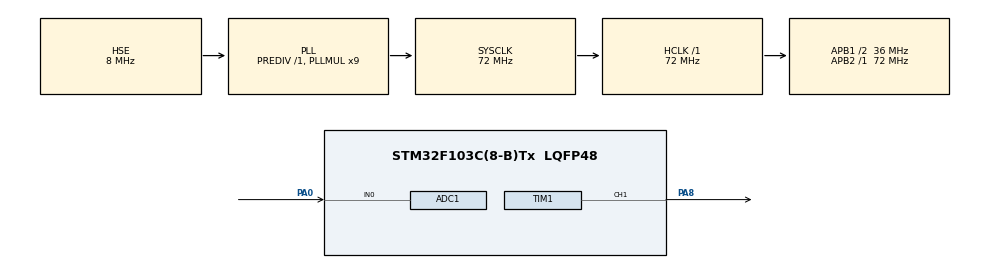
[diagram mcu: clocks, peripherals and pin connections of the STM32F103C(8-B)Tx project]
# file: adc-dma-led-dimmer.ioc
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ADC1.Channel-0\#ChannelRegularConversion=ADC_CHANNEL_0
ADC1.ContinuousConvMode=ENABLE
ADC1.NbrOfConversionFlag=1
ADC1.Rank-0\#ChannelRegularConversion=1
ADC1.SamplingTime-0\#ChannelRegularConversion=ADC_SAMPLETIME_1CYCLE_5
ADC1.master=1
Dma.ADC1.0.Direction=DMA_PERIPH_TO_MEMORY
Dma.ADC1.0.Instance=DMA1_Channel1
Dma.ADC1.0.MemDataAlignment=DMA_MDATAALIGN_WORD
Dma.ADC1.0.MemInc=DMA_MINC_ENABLE
Dma.ADC1.0.Mode=DMA_CIRCULAR
Dma.ADC1.0.PeriphDataAlignment=DMA_PDATAALIGN_WORD
Dma.ADC1.0.PeriphInc=DMA_PINC_DISABLE
Dma.ADC1.0.Priority=DMA_PRIORITY_LOW
Dma.Request0=ADC1
FREERTOS.BinarySemaphores01=adcSemaphore,Dynamic,NULL,Depleted
FREERTOS.Tasks01=defaultTask,24,128,StartDefaultTask,Default,NULL,Dynamic,NULL,NULL;ledCtrlTask,24,256,ledCtrlStrt,Default,NULL,Dynamic,NULL,NULL
FREERTOS.configTOTAL_HEAP_SIZE=10000
FREERTOS.configUSE_NEWLIB_REENTRANT=1
Mcu.Family=STM32F1
Mcu.Name=STM32F103C(8-B)Tx
Mcu.Package=LQFP48
NVIC.DMA1_Channel1_IRQn=true\:5\:0\:false\:false\:true\:true\:false\:true\:true
NVIC.PriorityGroup=NVIC_PRIORITYGROUP_4
NVIC.TIM2_IRQn=true\:15\:0\:false\:false\:true\:false\:false\:true\:true
NVIC.TimeBase=TIM2_IRQn
NVIC.TimeBaseIP=TIM2
PA0-WKUP.Signal=ADCx_IN0
PA8.Signal=S_TIM1_CH1
PD0-OSC_IN.Mode=HSE-External-Oscillator
PD0-OSC_IN.Signal=RCC_OSC_IN
PD1-OSC_OUT.Mode=HSE-External-Oscillator
PD1-OSC_OUT.Signal=RCC_OSC_OUT
ProjectManager.HeapSize=0x200
ProjectManager.StackSize=0x400
ProjectManager.TargetToolchain=STM32CubeIDE
RCC.ADCPresc=RCC_ADCPCLK2_DIV6
RCC.AHBFreq_Value=72000000
RCC.APB1CLKDivider=RCC_HCLK_DIV2
RCC.APB1Freq_Value=36000000
RCC.APB1TimFreq_Value=72000000
RCC.APB2Freq_Value=72000000
RCC.APB2TimFreq_Value=72000000
RCC.HCLKFreq_Value=72000000
RCC.PLLMUL=RCC_PLL_MUL9
RCC.PLLSourceVirtual=RCC_PLLSOURCE_HSE
RCC.SYSCLKFreq_VALUE=72000000
RCC.SYSCLKSource=RCC_SYSCLKSOURCE_PLLCLK
RCC.USBFreq_Value=72000000
SH.ADCx_IN0.0=ADC1_IN0,IN0
SH.S_TIM1_CH1.0=TIM1_CH1,PWM Generation1 CH1
TIM1.Channel-PWM\ Generation1\ CH1=TIM_CHANNEL_1
TIM1.Period=256 - 1
TIM1.Prescaler=72 - 1
VP_FREERTOS_VS_CMSIS_V2.Mode=CMSIS_V2
VP_SYS_VS_ND.Mode=No_Debug
VP_SYS_VS_tim2.Mode=TIM2
VP_TIM1_VS_ClockSourceINT.Mode=Internal
board=custom

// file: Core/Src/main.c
/* USER CODE BEGIN Header */
/**
  ******************************************************************************
  * @file           : main.c
  * @brief          : Main program body
  ******************************************************************************
  * @attention
  *
  * Copyright (c) 2024 STMicroelectronics.
  * All rights reserved.
  *
  * This software is licensed under terms that can be found in the LICENSE file
  * in the root directory of this software component.
  * If no LICENSE file comes with this software, it is provided AS-IS.
  *
  ******************************************************************************
  */
/* USER CODE END Header */
#include "main.h"
#include "cmsis_os.h"

/* USER CODE BEGIN PD */
#define BUFF_SIZE 16
/* USER CODE END PD */

ADC_HandleTypeDef hadc1;
DMA_HandleTypeDef hdma_adc1;

TIM_HandleTypeDef htim1;

/* Definitions for defaultTask */
osThreadId_t defaultTaskHandle;
const osThreadAttr_t defaultTask_attributes = {
  .name = "defaultTask",
  .stack_size = 128 * 4,
  .priority = (osPriority_t) osPriorityNormal,
};
/* Definitions for ledCtrlTask */
osThreadId_t ledCtrlTaskHandle;
const osThreadAttr_t ledCtrlTask_attributes = {
  .name = "ledCtrlTask",
  .stack_size = 256 * 4,
  .priority = (osPriority_t) osPriorityNormal,
};
/* Definitions for adcSemaphore */
osSemaphoreId_t adcSemaphoreHandle;
const osSemaphoreAttr_t adcSemaphore_attributes = {
  .name = "adcSemaphore"
};
/* USER CODE BEGIN PV */
volatile uint32_t adcBuff[BUFF_SIZE];
/* USER CODE END PV */

void SystemClock_Config(void);
static void MX_GPIO_Init(void);
static void MX_DMA_Init(void);
static void MX_ADC1_Init(void);
static void MX_TIM1_Init(void);
void StartDefaultTask(void *argument);
void ledCtrlStrt(void *argument);

int main(void)
{

  /* MCU Configuration--------------------------------------------------------*/

  /* Reset of all peripherals, Initializes the Flash interface and the Systick. */
  HAL_Init();

  /* Configure the system clock */
  SystemClock_Config();

  /* Initialize all configured peripherals */
  MX_GPIO_Init();
  MX_DMA_Init();
  MX_ADC1_Init();
  MX_TIM1_Init();
  /* USER CODE BEGIN 2 */
  //HAL_MspInit();
  HAL_TIM_PWM_Start(&htim1, TIM_CHANNEL_1);
  HAL_ADC_Start_DMA(&hadc1, adcBuff, BUFF_SIZE);
  //TIM1->CCR1 = 125;
  /* USER CODE END 2 */

  /* Init scheduler */
  osKernelInitialize();

  /* Create the semaphores(s) */
  /* creation of adcSemaphore */
  adcSemaphoreHandle = osSemaphoreNew(1, 0, &adcSemaphore_attributes);

  /* Create the thread(s) */
  /* creation of defaultTask */
  defaultTaskHandle = osThreadNew(StartDefaultTask, NULL, &defaultTask_attributes);

  /* creation of ledCtrlTask */
  ledCtrlTaskHandle = osThreadNew(ledCtrlStrt, NULL, &ledCtrlTask_attributes);

  /* Start scheduler */
  osKernelStart();

  /* We should never get here as control is now taken by the scheduler */

  /* Infinite loop */
  while (1)
  {

  }
}

void SystemClock_Config(void)
{
  RCC_OscInitTypeDef RCC_OscInitStruct = {0};
  RCC_ClkInitTypeDef RCC_ClkInitStruct = {0};
  RCC_PeriphCLKInitTypeDef PeriphClkInit = {0};

  /** Initializes the RCC Oscillators according to the specified parameters
  * in the RCC_OscInitTypeDef structure.
  */
  RCC_OscInitStruct.OscillatorType = RCC_OSCILLATORTYPE_HSE;
  RCC_OscInitStruct.HSEState = RCC_HSE_ON;
  RCC_OscInitStruct.HSEPredivValue = RCC_HSE_PREDIV_DIV1;
  RCC_OscInitStruct.HSIState = RCC_HSI_ON;
  RCC_OscInitStruct.PLL.PLLState = RCC_PLL_ON;
  RCC_OscInitStruct.PLL.PLLSource = RCC_PLLSOURCE_HSE;
  RCC_OscInitStruct.PLL.PLLMUL = RCC_PLL_MUL9;
  if (HAL_RCC_OscConfig(&RCC_OscInitStruct) != HAL_OK)
  {
    Error_Handler();
  }

  /** Initializes the CPU, AHB and APB buses clocks
  */
  RCC_ClkInitStruct.ClockType = RCC_CLOCKTYPE_HCLK|RCC_CLOCKTYPE_SYSCLK
                              |RCC_CLOCKTYPE_PCLK1|RCC_CLOCKTYPE_PCLK2;
  RCC_ClkInitStruct.SYSCLKSource = RCC_SYSCLKSOURCE_PLLCLK;
  RCC_ClkInitStruct.AHBCLKDivider = RCC_SYSCLK_DIV1;
  RCC_ClkInitStruct.APB1CLKDivider = RCC_HCLK_DIV2;
  RCC_ClkInitStruct.APB2CLKDivider = RCC_HCLK_DIV1;

  if (HAL_RCC_ClockConfig(&RCC_ClkInitStruct, FLASH_LATENCY_2) != HAL_OK)
  {
    Error_Handler();
  }
  PeriphClkInit.PeriphClockSelection = RCC_PERIPHCLK_ADC;
  PeriphClkInit.AdcClockSelection = RCC_ADCPCLK2_DIV6;
  if (HAL_RCCEx_PeriphCLKConfig(&PeriphClkInit) != HAL_OK)
  {
    Error_Handler();
  }
}

static void MX_ADC1_Init(void)
{

  ADC_ChannelConfTypeDef sConfig = {0};

  /** Common config
  */
  hadc1.Instance = ADC1;
  hadc1.Init.ScanConvMode = ADC_SCAN_DISABLE;
  hadc1.Init.ContinuousConvMode = ENABLE;
  hadc1.Init.DiscontinuousConvMode = DISABLE;
  hadc1.Init.ExternalTrigConv = ADC_SOFTWARE_START;
  hadc1.Init.DataAlign = ADC_DATAALIGN_RIGHT;
  hadc1.Init.NbrOfConversion = 1;
  if (HAL_ADC_Init(&hadc1) != HAL_OK)
  {
    Error_Handler();
  }

  /** Configure Regular Channel
  */
  sConfig.Channel = ADC_CHANNEL_0;
  sConfig.Rank = ADC_REGULAR_RANK_1;
  sConfig.SamplingTime = ADC_SAMPLETIME_1CYCLE_5;
  if (HAL_ADC_ConfigChannel(&hadc1, &sConfig) != HAL_OK)
  {
    Error_Handler();
  }
  /* USER CODE BEGIN ADC1_Init 2 */
  HAL_ADC_MspInit(&hadc1);
  /* USER CODE END ADC1_Init 2 */

}

static void MX_TIM1_Init(void)
{

  TIM_ClockConfigTypeDef sClockSourceConfig = {0};
  TIM_MasterConfigTypeDef sMasterConfig = {0};
  TIM_OC_InitTypeDef sConfigOC = {0};
  TIM_BreakDeadTimeConfigTypeDef sBreakDeadTimeConfig = {0};

  htim1.Instance = TIM1;
  htim1.Init.Prescaler = 72 - 1;
  htim1.Init.CounterMode = TIM_COUNTERMODE_UP;
  htim1.Init.Period = 256 - 1;
  htim1.Init.ClockDivision = TIM_CLOCKDIVISION_DIV1;
  htim1.Init.RepetitionCounter = 0;
  htim1.Init.AutoReloadPreload = TIM_AUTORELOAD_PRELOAD_DISABLE;
  if (HAL_TIM_Base_Init(&htim1) != HAL_OK)
  {
    Error_Handler();
  }
  sClockSourceConfig.ClockSource = TIM_CLOCKSOURCE_INTERNAL;
  if (HAL_TIM_ConfigClockSource(&htim1, &sClockSourceConfig) != HAL_OK)
  {
    Error_Handler();
  }
  if (HAL_TIM_PWM_Init(&htim1) != HAL_OK)
  {
    Error_Handler();
  }
  sMasterConfig.MasterOutputTrigger = TIM_TRGO_RESET;
  sMasterConfig.MasterSlaveMode = TIM_MASTERSLAVEMODE_DISABLE;
  if (HAL_TIMEx_MasterConfigSynchronization(&htim1, &sMasterConfig) != HAL_OK)
  {
    Error_Handler();
  }
  sConfigOC.OCMode = TIM_OCMODE_PWM1;
  sConfigOC.Pulse = 0;
  sConfigOC.OCPolarity = TIM_OCPOLARITY_HIGH;
  sConfigOC.OCNPolarity = TIM_OCNPOLARITY_HIGH;
  sConfigOC.OCFastMode = TIM_OCFAST_DISABLE;
  sConfigOC.OCIdleState = TIM_OCIDLESTATE_RESET;
  sConfigOC.OCNIdleState = TIM_OCNIDLESTATE_RESET;
  if (HAL_TIM_PWM_ConfigChannel(&htim1, &sConfigOC, TIM_CHANNEL_1) != HAL_OK)
  {
    Error_Handler();
  }
  sBreakDeadTimeConfig.OffStateRunMode = TIM_OSSR_DISABLE;
  sBreakDeadTimeConfig.OffStateIDLEMode = TIM_OSSI_DISABLE;
  sBreakDeadTimeConfig.LockLevel = TIM_LOCKLEVEL_OFF;
  sBreakDeadTimeConfig.DeadTime = 0;
  sBreakDeadTimeConfig.BreakState = TIM_BREAK_DISABLE;
  sBreakDeadTimeConfig.BreakPolarity = TIM_BREAKPOLARITY_HIGH;
  sBreakDeadTimeConfig.AutomaticOutput = TIM_AUTOMATICOUTPUT_DISABLE;
  if (HAL_TIMEx_ConfigBreakDeadTime(&htim1, &sBreakDeadTimeConfig) != HAL_OK)
  {
    Error_Handler();
  }
  /* USER CODE BEGIN TIM1_Init 2 */
  //HAL_TIM_Base_MspInit(&htim1);
  /* USER CODE END TIM1_Init 2 */
  HAL_TIM_MspPostInit(&htim1);

}

static void MX_DMA_Init(void)
{

  /* DMA controller clock enable */
  __HAL_RCC_DMA1_CLK_ENABLE();

  /* DMA interrupt init */
  /* DMA1_Channel1_IRQn interrupt configuration */
  HAL_NVIC_SetPriority(DMA1_Channel1_IRQn, 5, 0);
  HAL_NVIC_EnableIRQ(DMA1_Channel1_IRQn);

}

static void MX_GPIO_Init(void)
{

  /* GPIO Ports Clock Enable */
  __HAL_RCC_GPIOD_CLK_ENABLE();
  __HAL_RCC_GPIOA_CLK_ENABLE();

}

/* USER CODE BEGIN 4 */
void HAL_ADC_ConvCpltCallback(ADC_HandleTypeDef* hadc) {
	osSemaphoreRelease(adcSemaphoreHandle);
	osDelay(1);
	osSemaphoreAcquire(adcSemaphoreHandle, osWaitForever);
}
/* USER CODE END 4 */

void StartDefaultTask(void *argument)
{
  for(;;)
  {
    osDelay(1);
  }
}

void ledCtrlStrt(void *argument)
{
  /* USER CODE BEGIN ledCtrlStrt */
  /* Infinite loop */
  for(;;)
  {
	  osSemaphoreAcquire(adcSemaphoreHandle, osWaitForever);

	  for (int i = 0; i < BUFF_SIZE; i++) {
	  	uint32_t val = adcBuff[i] / 15; //dividing by 15 ensures 100% DC can be reached
	  	__HAL_TIM_SET_COMPARE(&htim1, TIM_CHANNEL_1, val);
	  }

	  osSemaphoreRelease(adcSemaphoreHandle);

	  osDelay(1);
  }
  /* USER CODE END ledCtrlStrt */
}

void HAL_TIM_PeriodElapsedCallback(TIM_HandleTypeDef *htim)
{
  if (htim->Instance == TIM2) {
    HAL_IncTick();
  }
}

void Error_Handler(void)
{
  __disable_irq();
  while (1)
  {
  }
}
